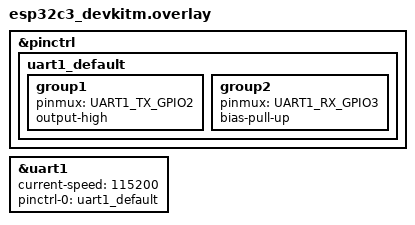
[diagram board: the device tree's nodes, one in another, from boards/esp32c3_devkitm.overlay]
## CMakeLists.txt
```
#-------------------------------------------------------------------------------
# Zephyr Example Application
#
# Copyright (c) 2021 Nordic Semiconductor ASA
# SPDX-License-Identifier: Apache-2.0

cmake_minimum_required(VERSION 3.13.1)
find_package(Zephyr REQUIRED HINTS $ENV{ZEPHYR_BASE})

project(app LANGUAGES C)

target_sources(app PRIVATE src/main.c)

add_subdirectory(src/bt)
add_subdirectory(src/uart)
```

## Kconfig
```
# Copyright (c) 2021 Nordic Semiconductor ASA
# SPDX-License-Identifier: Apache-2.0
#
# This file is the application Kconfig entry point. All application Kconfig
# options can be defined here or included via other application Kconfig files.
# You can browse these options using the west targets menuconfig (terminal) or
# guiconfig (GUI).

menu "Zephyr"
source "Kconfig.zephyr"
endmenu

module = APP
module-str = APP
source "subsys/logging/Kconfig.template.log_config"
    
```

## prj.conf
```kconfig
CONFIG_BT=y
CONFIG_BT_CENTRAL=y
CONFIG_BT_GATT_CLIENT=y
CONFIG_LOG=y
CONFIG_SERIAL=y
CONFIG_UART_INTERRUPT_DRIVEN=y

CONFIG_APP_BLE_CONN_BY_ADDR=n
# CONFIG_APP_BLE_PERIPH_ADDR="58:CF:79:E3:62:74"
```

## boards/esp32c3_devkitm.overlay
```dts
&pinctrl {
    uart1_default: uart1_default {
        group1 {
			pinmux = <UART1_TX_GPIO2>;
			output-high;
		};
		group2 {
			pinmux = <UART1_RX_GPIO3>;
			bias-pull-up;
		};
    };
};

&uart1 {
    status = "okay";
	current-speed = <115200>;
	pinctrl-0 = <&uart1_default>;
	pinctrl-names = "default";
};
```

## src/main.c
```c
#include <zephyr/kernel.h>
#include <zephyr/logging/log.h>

#include "bt.h"
#include "uart.h"

#define INIT_DELAY_MS (1000U)

LOG_MODULE_REGISTER(main, LOG_LEVEL_DBG);

static void uart_rx_cb(const uint8_t *p_rx_buf, size_t len)
{
	if (p_rx_buf)
	{
		uart_cmd_t cmd = (uart_cmd_t) p_rx_buf[0];
		switch (cmd)
		{
			default:
				// Ignore all commands
			break;
		}
	}
}

static void notif_rcv_cb(const void *data, uint16_t len)
{
	LOG_DBG("Received data of size %u", len);
	uart_send_data((const uint8_t *) data, len);
}

static void bt_connected_cb(void)
{
	LOG_INF("tHE BLuEToOTH DeVIcE IS COnNEcTED");
	uart_send_cmd(UART_CMD_CONN_OK);
}

int main(void)
{
	LOG_DBG("Start");

	uart_register_rx_cb(uart_rx_cb);
	
	k_msleep(INIT_DELAY_MS);

	bt_register_notif_rcv_cb(notif_rcv_cb);
	bt_start(bt_connected_cb);

	return 0;
}
```
